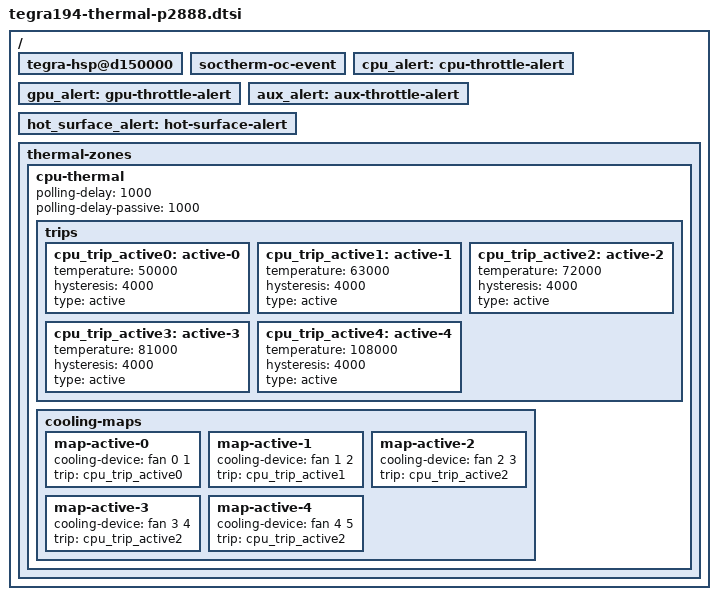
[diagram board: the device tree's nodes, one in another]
/*
 * Copyright (c) 2017-2022, NVIDIA CORPORATION.  All rights reserved.
 *
 * This program is free software; you can redistribute it and/or modify it
 * under the terms and conditions of the GNU General Public License,
 * version 2, as published by the Free Software Foundation.
 *
 * This program is distributed in the hope it will be useful, but WITHOUT
 * ANY WARRANTY; without even the implied warranty of MERCHANTABILITY or
 * FITNESS FOR A PARTICULAR PURPOSE.  See the GNU General Public License for
 * more details.
 *
 * You should have received a copy of the GNU General Public License
 * along with this program.  If not, see <http://www.gnu.org/licenses/>.
 */

#include <t19x-common-platforms/tegra194-thermal.dtsi>
#include <t19x-common-platforms/tegra194-thermal-userspace-alert.dtsi>
#include "tegra194-spmic-p2888-0001.dtsi"
/ {
	tegra-hsp@d150000 {
		status = "okay";
	};

	soctherm-oc-event {
		status = "okay";
	};

	cpu_alert: cpu-throttle-alert {
		status = "okay";
	};

	gpu_alert: gpu-throttle-alert {
		status = "okay";
	};

	aux_alert: aux-throttle-alert {
		status = "okay";
	};

	hot_surface_alert: hot-surface-alert {
		status = "okay";
	};

	thermal-zones {
		status = "okay";

		cpu-thermal {
			polling-delay = <1000>;
			polling-delay-passive = <1000>;
			status = "okay";

			trips {
				cpu_trip_active0: active-0 {
					temperature = <50000>;
					hysteresis = <4000>;
					type = "active";
				};

				cpu_trip_active1: active-1 {
					temperature = <63000>;
					hysteresis = <4000>;
					type = "active";
				};

				cpu_trip_active2: active-2 {
					temperature = <72000>;
					hysteresis = <4000>;
					type = "active";
				};

				cpu_trip_active3: active-3 {
					temperature = <81000>;
					hysteresis = <4000>;
					type = "active";
				};

				cpu_trip_active4: active-4 {
					temperature = <108000>;
					hysteresis = <4000>;
					type = "active";
				};
			};

			cooling-maps {
				map-active-0 {
					cooling-device = <&fan 0 1>;
					trip = <&cpu_trip_active0>;
				};

				map-active-1 {
					cooling-device = <&fan 1 2>;
					trip = <&cpu_trip_active1>;
				};

				map-active-2 {
					cooling-device = <&fan 2 3>;
					trip = <&cpu_trip_active2>;
				};

				map-active-3 {
					cooling-device = <&fan 3 4>;
					trip = <&cpu_trip_active2>;
				};

				map-active-4 {
					cooling-device = <&fan 4 5>;
					trip = <&cpu_trip_active2>;
				};
			};
		};
	};
};

